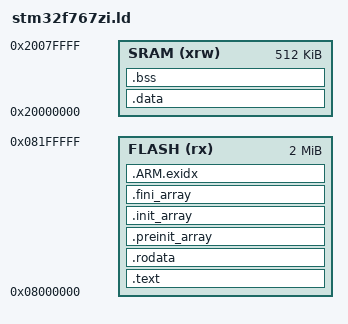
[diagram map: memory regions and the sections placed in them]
MEMORY
{
    FLASH (rx) : ORIGIN = 0x08000000, LENGTH = 2048K
     SRAM (xrw)      : ORIGIN = 0x20000000, LENGTH = 512K
}

OUTPUT_FORMAT("elf32-littlearm", "elf32-bigarm","elf32-littlearm") 
OUTPUT_ARCH(arm)

PROVIDE(hardware_init_hook = 0);
PROVIDE(software_init_hook = 0);
PROVIDE(software_term_hook = 0);

ENTRY(_kernel_start)

SECTIONS
{
    .text :
    {
        __text = . ; 
        *(.vector)
        . = ALIGN(16);
        *(.text*)
        KEEP(*(.empty.*))
        *(.glue_7t)
        *(.glue_7)

        KEEP(*(.init))
        KEEP(*(.fini))

        /* .ctors */
        *crtbegin.o(.ctors)
        *crtbegin?.o(.ctors)
        *(EXCLUDE_FILE(*crtend?.o *crtend.o) .ctors)
        *(SORT(.ctors.*))
        *(.ctors)

        /* .dtors */
        *crtbegin.o(.dtors)
        *crtbegin?.o(.dtors)
        *(EXCLUDE_FILE(*crtend?.o *crtend.o) .dtors)
        *(SORT(.dtors.*))
        *(.dtors)
    } > FLASH
    _etext = .	;
    PROVIDE (etext = .)	;

    .rodata : { 
        *(.rodata*) 
    } > FLASH

    .preinit_array ALIGN(4) : {
        PROVIDE_HIDDEN (__preinit_array_start = .);
        KEEP (*(.preinit_array))
        PROVIDE_HIDDEN (__preinit_array_end = .);
    } > FLASH
    .init_array ALIGN(4) : {
        PROVIDE_HIDDEN (__init_array_start = .);
        KEEP (*(SORT(.init_array.*)))
        KEEP (*(.init_array))
        PROVIDE_HIDDEN (__init_array_end = .);
    } > FLASH
    .fini_array ALIGN(4) : {
        PROVIDE_HIDDEN (__fini_array_start = .);
        KEEP (*(SORT(.fini_array.*)))
        KEEP (*(.fini_array))
        PROVIDE_HIDDEN (__fini_array_end = .);
    } > FLASH
    .ARM.exidx ALIGN(4) : {
        __exidx_start = .;
        *(.ARM.exidx* .gnu.linkonce.armexidx.*)
        __exidx_end = .;
    } > FLASH

    . = ALIGN(4);
    __idata_start = . ;
    .data   :  AT(__idata_start) 
    {
        __data_start = . ;
        *(vtable)
        *(.data*)
    } > SRAM
    __idata_end = __idata_start + SIZEOF(.data);
    _edata  =  . ;
    PROVIDE (edata = .);
    . = ALIGN(4);

    .bss       :
    {
       __bss_start = .	;
      *(.bss*)
      *(COMMON)
      . = ALIGN(32 / 8);
    } > SRAM
   . = ALIGN(32 / 8);
     _end = .		;
    __bss_end = .;
    PROVIDE (end = .)	;

    .comment 0 : { *(.comment) }

  /* DWARF debug sections.
     Symbols in the DWARF debugging sections are relative to 
     the beginning of the section so we begin them at 0.  */

  /* DWARF 1 */
  .debug          0 : { *(.debug) }
  .line           0 : { *(.line) }

  /* GNU DWARF 1 extensions */
  .debug_srcinfo  0 : { *(.debug_srcinfo) }
  .debug_sfnames  0 : { *(.debug_sfnames) }

  /* DWARF 1.1 and DWARF 2 */
  .debug_aranges  0 : { *(.debug_aranges) }
  .debug_pubnames 0 : { *(.debug_pubnames) }

  /* DWARF 2 */
  .debug_info     0 : { *(.debug_info) }
  .debug_abbrev   0 : { *(.debug_abbrev) }
  .debug_line     0 : { *(.debug_line) }
  .debug_frame    0 : { *(.debug_frame) }
  .debug_str      0 : { *(.debug_str) }
  .debug_loc      0 : { *(.debug_loc) }
  .debug_macinfo  0 : { *(.debug_macinfo) }

  /* SGI/MIPS DWARF 2 extensions */
  .debug_weaknames 0 : { *(.debug_weaknames) }
  .debug_funcnames 0 : { *(.debug_funcnames) }
  .debug_typenames 0 : { *(.debug_typenames) }
  .debug_varnames  0 : { *(.debug_varnames) }
}
